# MK70F15WS register map
File version: 1.6
Registers are 32-bit, read-write, reset 0x0 unless marked. A register's access mark holds for its fields unless they carry their own. Offsets are from the block's base; [hi:lo] are bit positions; 'fields as' and 'values as' point back to an identical list.

## LCDC — Liquid Crystal Display Controller
Base 0x400B6000; register names take the prefix LCDC_
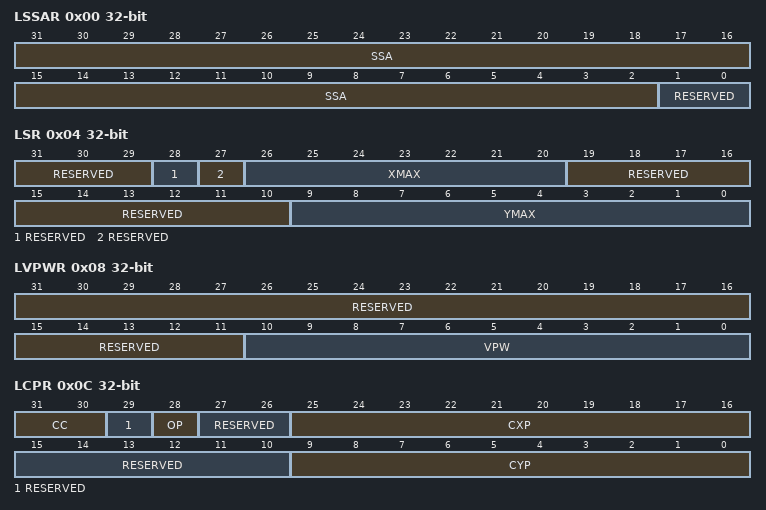
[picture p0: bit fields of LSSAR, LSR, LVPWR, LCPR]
0x00 LSSAR — LCDC screen start address register
  [31:2] SSA — Screen start address of LCD panel
  [1:0] RESERVED ro
0x04 LSR — LCDC size register
  [31:29] RESERVED ro
  [28] RESERVED ro
  [27] RESERVED ro
  [26:20] XMAX — Screen width divided by 16
  [19:10] RESERVED ro
  [9:0] YMAX — Screen height
0x08 LVPWR — LCDC virtual page width register
  [31:11] RESERVED ro
  [10:0] VPW — Virtual page width
0x0C LCPR — LCDC cursor position register
  [31:30] CC — Cursor control
  [29] RESERVED ro
  [28] OP — Arithmetic operation control
    0=Disable arithmetic operation; 1=Enable arithmetic operation
  [27:26] RESERVED ro
  [25:16] CXP — Cursor X position
  [15:10] RESERVED ro
  [9:0] CYP — Cursor Y position
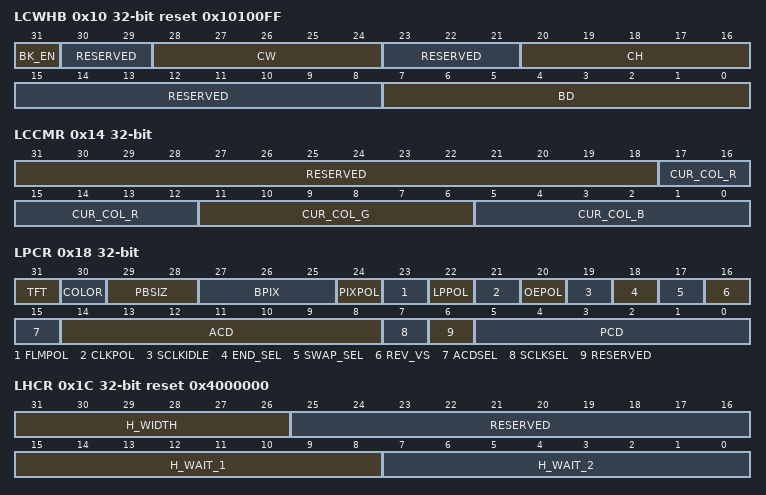
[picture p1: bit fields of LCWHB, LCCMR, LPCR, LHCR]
0x10 LCWHB reset 0x10100FF — LCDC cursor width, height, and blink register
  [31] BK_EN — Blink enable
    0=Blink is disabled; 1=Blink is enabled
  [30:29] RESERVED ro
  [28:24] CW — Cursor width
  [23:21] RESERVED ro
  [20:16] CH — Cursor height
  [15:8] RESERVED ro
  [7:0] BD — Blink divisor
0x14 LCCMR — LCDC color cursor mapping register
  [31:18] RESERVED ro
  [17:12] CUR_COL_R — Cursor red field
    0=No red; 63=Full red
  [11:6] CUR_COL_G — Cursor green field
    0=No green; 63=Full green
  [5:0] CUR_COL_B — Cursor blue field
    0=No blue; 63=Full blue
0x18 LPCR — LCDC panel configuration register
  [31] TFT — Interfaces to TFT display
    0=LCD panel is a passive display; 1=LCD panel is an active display: "digital CRT" signal format, FRC is bypassed
  [30] COLOR — Interfaces to color display
    0=LCD panel is a Monochrome display; 1=LCD panel is a Color display
  [29:28] PBSIZ — Panel bus width
    0=1-bit; 1=2-bit; 2=4-bit; 3=8-bit
  [27:25] BPIX — Bits per pixel
    0=1 bpp, FRC bypassed; 1=2 bpp; 2=4 bpp; 3=8 bpp; 4=12 bpp (16-bits of memory used); 5=16 bpp; 6=18 bpp (32-bits of memory used); 7=24 bpp (32-bits of memory used)
  [24] PIXPOL — Pixel polarity
    0=Active high; 1=Active low
  [23] FLMPOL — First line marker polarity
    0=Active high; 1=Active low
  [22] LPPOL — Line pulse polarity
    0=Active high; 1=Active low
  [21] CLKPOL — LCD shift clock polarity
    0=Active on negative edge of LSCLK. In TFT mode, active on positive edge of LSCLK.; 1=Active on positive edge of LSCLK. In TFT mode, active on negative edge of LSCLK.
  [20] OEPOL — Output enable polarity
    0=Active high; 1=Active low
  [19] SCLKIDLE — LSCLK idle enable
    0=Disable LSCLK; 1=Enable LSCLK
  [18] END_SEL — Endian select
    0=Little Endian; 1=Big Endian
  [17] SWAP_SEL — Swap select
    0=24 bpp, 18 bpp, 16 bpp, 12 bpp mode; 1=8 bpp, 4 bpp, 2 bpp, and 1 bpp mode
  [16] REV_VS — Reverse vertical scan
    0=Vertical scan in normal direction; 1=Vertical scan in reverse direction
  [15] ACDSEL — ACD clock source select
    0=Use FLM as a clock source for ACD count; 1=Use LP/HSYNC as a clock source for ACD count
  [14:8] ACD — Alternate crystal direction
  [7] SCLKSEL — LSCLK select
    0=Disable OE and LSCLK in TFT mode when no data output; 1=Always enable LSCLK in TFT mode even if there is no data output
  [6] RESERVED ro
  [5:0] PCD — Pixel clock divider
0x1C LHCR reset 0x4000000 — LCDC horizontal configuration register
  [31:26] H_WIDTH — Horizontal sync pulse width
  [25:16] RESERVED ro
  [15:8] H_WAIT_1 — Wait between OE and HSYNC
  [7:0] H_WAIT_2 — Wait between HSYNC and start of next line
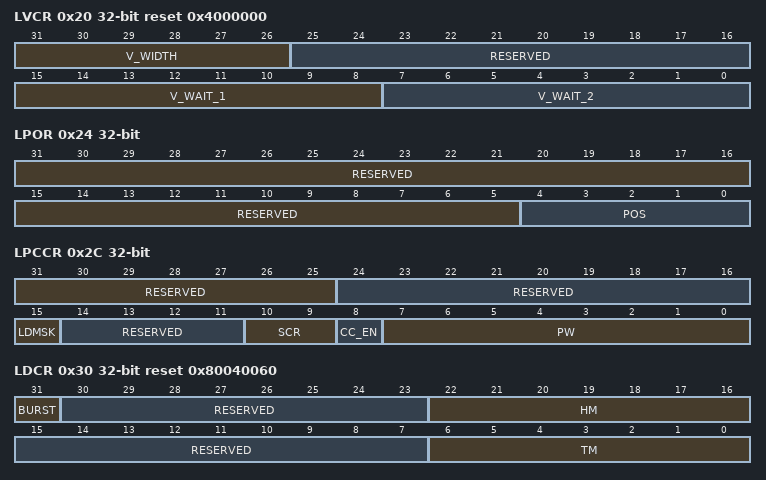
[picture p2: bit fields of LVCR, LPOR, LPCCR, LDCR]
0x20 LVCR reset 0x4000000 — LCDC vertical configuration register
  [31:26] V_WIDTH — Vertical sync pulse width
  [25:16] RESERVED ro
  [15:8] V_WAIT_1 — Wait between frames 1
  [7:0] V_WAIT_2 — Wait between frames 2
0x24 LPOR — LCDC panning offset register
  [31:5] RESERVED ro
  [4:0] POS — Panning offset
0x2C LPCCR — LCDC PWM contrast control register
  [31:25] RESERVED ro
  [24:16] RESERVED ro
  [15] LDMSK — LD mask
    0=LD [23:0] is normal; 1=LD [23:0] always equals 0
  [14:11] RESERVED ro
  [10:9] SCR — Source select
    0=Line pulse; 1=Pixel clock; 2=LCD clock
  [8] CC_EN — Contrast control enable
    0=Contrast control is off; 1=Contrast control is on
  [7:0] PW — Pulse-width
0x30 LDCR reset 0x80040060 — LCDC DMA control register
  [31] BURST — Burst length
    0=Burst length is dynamic; 1=Burst length is fixed
  [30:23] RESERVED ro
  [22:16] HM — DMA high mark
  [15:7] RESERVED ro
  [6:0] TM — DMA trigger mark
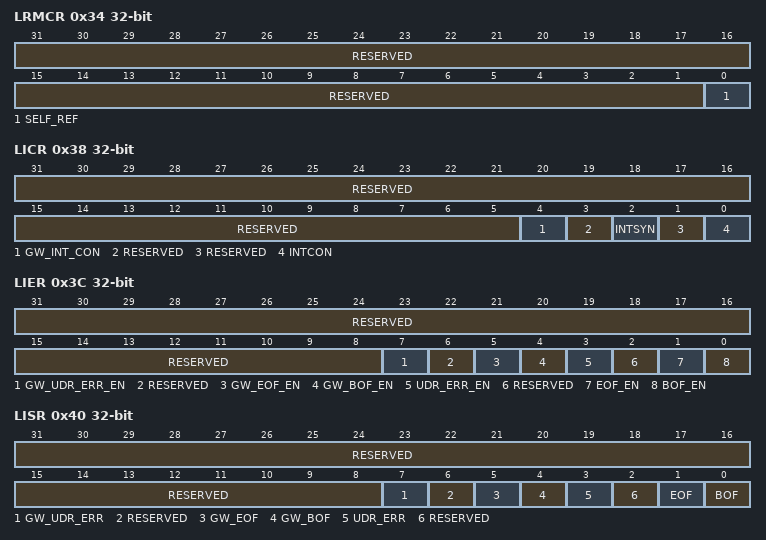
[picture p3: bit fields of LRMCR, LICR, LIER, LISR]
0x34 LRMCR — LCDC refresh mode control register
  [31:1] RESERVED ro
  [0] SELF_REF — Self-refresh
    0=Disable self-refresh; 1=Enable self-refresh
0x38 LICR — LCDC interrupt configuration register
  [31:5] RESERVED ro
  [4] GW_INT_CON — Graphic window interrupt condition
    0=Interrupt flag is set when end of graphic window is reached; 1=Interrupt flag is set when beginning of graphic window is reached
  [3] RESERVED ro
  [2] INTSYN — Interrupt source
    0=Interrupt flag is set on loading the last/first data of frame from memory; 1=Interrupt flag is set on output of the last/first data of frame to LCD panel
  [1] RESERVED ro
  [0] INTCON — Interrupt condition
    0=Interrupt flag is set when the end of frame (EOF) is reached; 1=Interrupt flag is set when the beginning of frame (BOF) is reached
0x3C LIER — LCDC interrupt enable register
  [31:8] RESERVED ro
  [7] GW_UDR_ERR_EN — Graphic window under run error interrupt enable
    0=Mask interrupt; 1=Enable interrupt
  [6] RESERVED ro
  [5] GW_EOF_EN — Graphic window end of frame interrupt enable
    0=Mask interrupt; 1=Enable interrupt
  [4] GW_BOF_EN — Graphic window beginning of frame interrupt enable
    0=Mask interrupt; 1=Enable interrupt
  [3] UDR_ERR_EN — Under run error interrupt enable
    0=Mask interrupt; 1=Enable interrupt
  [2] RESERVED ro
  [1] EOF_EN — End of frame interrupt enable
    0=Mask interrupt; 1=Enable interrupt
  [0] BOF_EN — Beginning of frame interrupt enable
    0=Mask interrupt; 1=Enable interrupt
0x40 LISR ro — LCDC interrupt status register
  [31:8] RESERVED
  [7] GW_UDR_ERR — Graphic window under run error
    0=Graphic window under run has not occurred; 1=Graphic window under run has occurred
  [6] RESERVED
  [5] GW_EOF — Graphic window end of frame
    0=Interrupt has not occurred; 1=Interrupt has occurred
  [4] GW_BOF — Graphic window beginning of frame
    0=Interrupt has not occurred; 1=Interrupt has occurred
  [3] UDR_ERR — Under run error
    0=Interrupt has not occurred; 1=Interrupt has occurred
  [2] RESERVED
  [1] EOF — End of frame
    0=Interrupt has not occurred; 1=Interrupt has occurred
  [0] BOF — Beginning of frame
    0=Interrupt has not occurred; 1=Interrupt has occurred
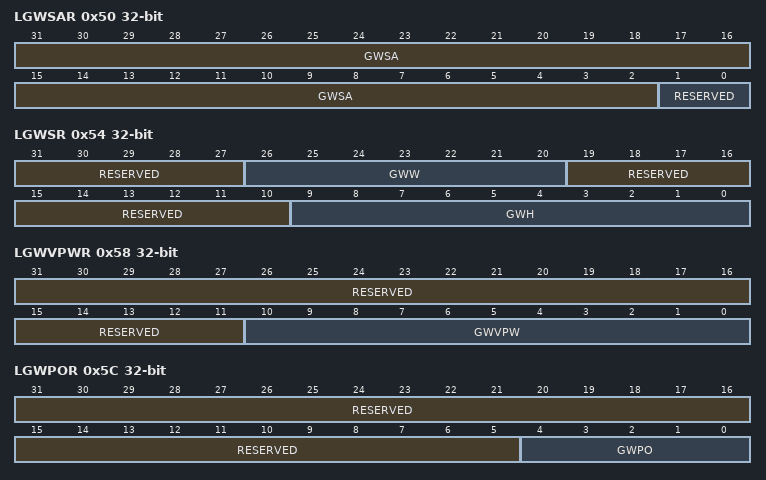
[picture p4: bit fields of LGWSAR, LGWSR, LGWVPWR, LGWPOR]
0x50 LGWSAR — LCDC graphic window start address register
  [31:2] GWSA — Graphic window start address on LCD screen
  [1:0] RESERVED ro
0x54 LGWSR — LCDC graphic window size register
  [31:27] RESERVED ro
  [26:20] GWW — Graphic window width divided by 16
  [19:10] RESERVED ro
  [9:0] GWH — Graphic window height
0x58 LGWVPWR — LCDC graphic window virtual page width register
  [31:11] RESERVED ro
  [10:0] GWVPW — Graphic window virtual page width
0x5C LGWPOR — LCDC graphic window panning offset register
  [31:5] RESERVED ro
  [4:0] GWPO — Graphic window panning offset
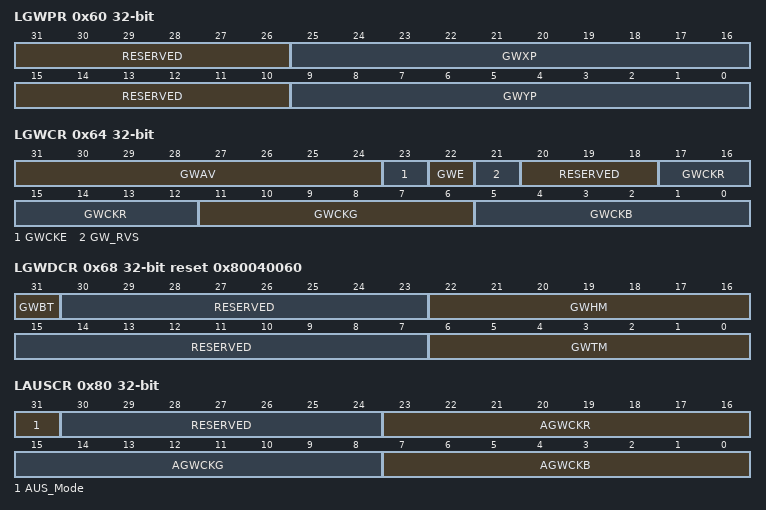
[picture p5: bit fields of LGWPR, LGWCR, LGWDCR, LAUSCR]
0x60 LGWPR — LCDC graphic window position register
  [31:26] RESERVED ro
  [25:16] GWXP — Graphic window X position
  [15:10] RESERVED ro
  [9:0] GWYP — Graphic window Y position
0x64 LGWCR — LCDC graphic window control register
  [31:24] GWAV — Graphic window alpha value
    0=Graphic window totally transparent (not displayed on LCD screen); 1=Graphic window totally opaque (completely visible on LCD screen)
  [23] GWCKE — Graphic window color keying enable
    0=Disable color keying of graphic window; 1=Enable color keying of graphic window
  [22] GWE — Graphic window enable
    0=Disable graphic window on screen; 1=Enable graphic window on screen
  [21] GW_RVS — Graphic window reverse vertical scan
    values as LPCR.REV_VS
  [20:18] RESERVED ro
  [17:12] GWCKR — Graphic window color keying red component
    0=No red; 63=Full red
  [11:6] GWCKG — Graphic window color keying green component
    0=No green; 63=Full green
  [5:0] GWCKB — Graphic window color keying blue component
    0=No blue; 63=Full blue
0x68 LGWDCR reset 0x80040060 — LCDC graphic window DMA control register
  [31] GWBT — Graphic window DMA burst type
    0=Burst length is dynamic; 1=Burst length is fixed
  [30:23] RESERVED ro
  [22:16] GWHM — Graphic window DMA high mark
  [15:7] RESERVED ro
  [6:0] GWTM — Graphic window DMA low mark
0x80 LAUSCR — LCDC AUS mode control register
  [31] AUS_Mode — AUS mode control
    0=Normal mode; 1=AUS mode
  [30:24] RESERVED ro
  [23:16] AGWCKR — AUS graphic window color keying red component
  [15:8] AGWCKG — AUS graphic window color keying green component
  [7:0] AGWCKB — AUS graphic window color keying blue component
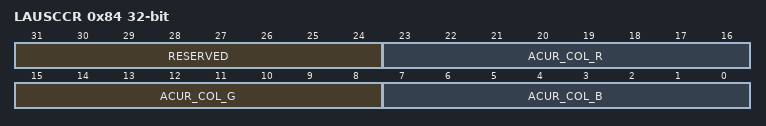
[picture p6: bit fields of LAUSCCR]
0x84 LAUSCCR — LCDC AUS mode cursor control register
  [31:24] RESERVED ro
  [23:16] ACUR_COL_R — AUS cursor red field
  [15:8] ACUR_COL_G — AUS cursor green field
  [7:0] ACUR_COL_B — AUS cursor red field
